# EFR32MG24A020F1536IM40 register map
Vendor: Silicon Labs; Series: EFR32; File version: B
Registers are 32-bit, read-write, reset 0x0 unless marked. A register's access mark holds for its fields unless they carry their own. Offsets are from the block's base; [hi:lo] are bit positions; {n}, {i} and the like mark numbered series; 'fields as' and 'values as' point back to an identical list.

## MSC_NS — MSC_NS Registers
Base 0x50030000
Same registers: MSC_S 0x40030000
0x00 IPVERSION ro reset 0x3
  [31:0] IPVERSION — IP Version ID
0x04 READCTRL reset 0x200000
  [21:20] MODE — Read Mode
    0=WS0 (Zero wait-states inserted in fetch or read transfers); 1=WS1 (One wait-state inserted for each fetch or read transfer. See Flash Wait-States table for details); 2=WS2 (Two wait-states inserted for eatch fetch or read transfer. See Flash Wait-States table for details); 3=WS3 (Three wait-states inserted for eatch fetch or read transfer. See Flash Wait-States table for details)
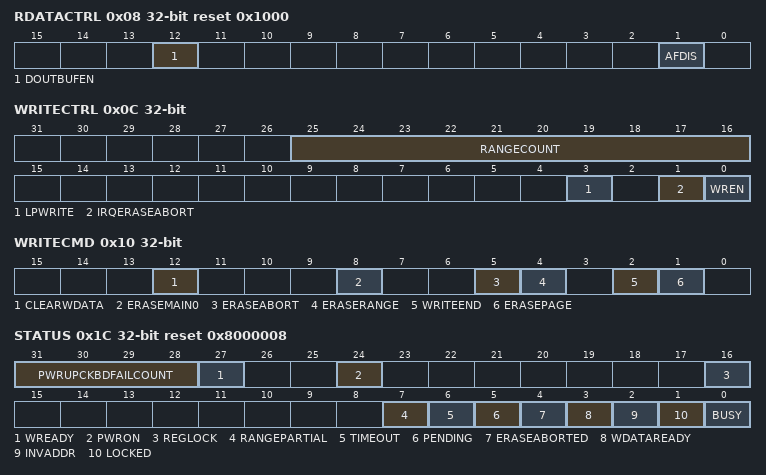
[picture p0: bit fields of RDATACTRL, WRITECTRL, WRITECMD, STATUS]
0x08 RDATACTRL reset 0x1000
  [12] DOUTBUFEN — Flash dout pipeline buffer enable
  [1] AFDIS — Automatic Invalidate Disable
0x0C WRITECTRL
  [25:16] RANGECOUNT — EraseRange Count
  [3] LPWRITE — Low-Power Write
  [1] IRQERASEABORT — Abort Page Erase on Interrupt
  [0] WREN — Enable Write/Erase Controller
0x10 WRITECMD wo
  [12] CLEARWDATA — Clear WDATA state
  [8] ERASEMAIN0 — Mass erase region 0
  [5] ERASEABORT — Abort erase sequence
  [4] ERASERANGE — Erase range of pages
  [2] WRITEEND — End Write Mode
  [1] ERASEPAGE
0x14 ADDRB
  [31:0] ADDRB — Page Erase or Write Address Buffer
0x18 WDATA
  [31:0] DATAW — Write Data
0x1C STATUS ro reset 0x8000008
  [31:28] PWRUPCKBDFAILCOUNT — Flash power up checkerboard pattern chec
  [27] WREADY — Flash Write Ready
  [24] PWRON — Flash power on status
  [16] REGLOCK — Register Lock Status
    0=UNLOCKED; 1=LOCKED
  [7] RANGEPARTIAL — EraseRange with skipped locked pages
  [6] TIMEOUT — Write Command Timeout
  [5] PENDING — Write Command In Queue
  [4] ERASEABORTED — Erase Operation Aborted
  [3] WDATAREADY — WDATA Write Ready
  [2] INVADDR — Invalid Write Address or Erase Page
  [1] LOCKED — Access Locked
  [0] BUSY — Erase/Write Busy
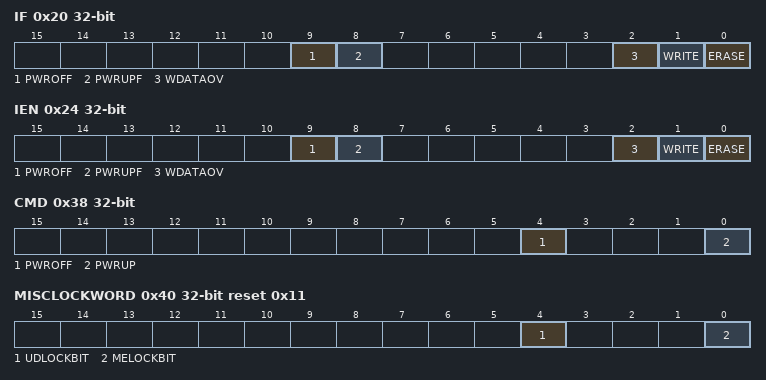
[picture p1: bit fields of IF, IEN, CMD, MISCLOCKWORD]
0x20 IF
  [9] PWROFF — Flash Power Off Sequence Complete Flag
  [8] PWRUPF — Flash Power Up Sequence Complete Flag
  [2] WDATAOV — Host write buffer overflow
  [1] WRITE — Host Write Done Interrupt Read Flag
  [0] ERASE — Host Erase Done Interrupt Read Flag
0x24 IEN
  [9] PWROFF — Flash Power Off Seq done irq enable
  [8] PWRUPF — Flash Power Up Seq done irq enable
  [2] WDATAOV — write data buffer overflow irq enable
  [1] WRITE — Write Done Interrupt enable
  [0] ERASE — Erase Done Interrupt enable
0x34 USERDATASIZE ro reset 0x4
  [5:0] USERDATASIZE
0x38 CMD wo
  [4] PWROFF — Flash power off/sleep command
  [0] PWRUP — Flash Power Up Command
0x3C LOCK wo
  [15:0] LOCKKEY — Configuration Lock
    0=LOCK; 0x1B71=UNLOCK
0x40 MISCLOCKWORD reset 0x11
  [4] UDLOCKBIT — User Data Lock
  [0] MELOCKBIT — Mass Erase Lock
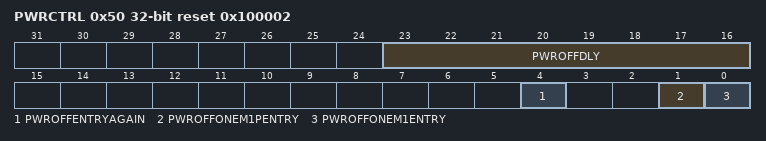
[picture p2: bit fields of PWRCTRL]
0x50 PWRCTRL reset 0x100002
  [23:16] PWROFFDLY — Power down delay
  [4] PWROFFENTRYAGAIN — POWER down flash again in EM1/EM1p
  [1] PWROFFONEM1PENTRY — Power down Flash macro when enter EM1P
  [0] PWROFFONEM1ENTRY — Power down Flash macro when enter EM1
{0x120+4i} PAGELOCK{i} (i=0..5)
  [31:0] LOCKBIT — page lock bit

## PCNT0_NS — PCNT0_NS Registers
Base 0x59030000
Same registers: PCNT0_S 0x49030000
0x00 IPVERSION ro reset 0x1
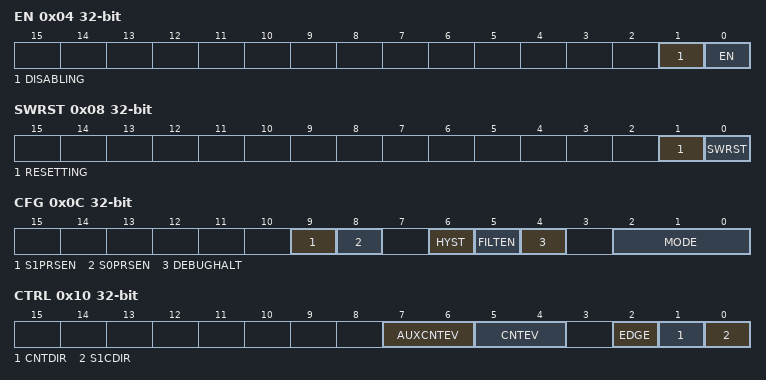
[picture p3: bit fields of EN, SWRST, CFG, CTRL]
0x04 EN
  [1] DISABLING ro — Disablement busy status
  [0] EN — PCNT Module Enable
0x08 SWRST
  [1] RESETTING ro — Software reset busy status
  [0] SWRST wo — Software reset command
0x0C CFG
  [9] S1PRSEN — S1IN PRS Enable
  [8] S0PRSEN — S0IN PRS Enable
  [6] HYST — Enable Hysteresis
  [5] FILTEN — Enable Digital Pulse Width Filter
  [4] DEBUGHALT — Debug Mode Halt Enable
    0=DISABLE (PCNT is running in debug mode.); 1=ENABLE (PCNT is frozen in debug mode.)
  [2:0] MODE — Mode Select
    0=OVSSINGLE (Single input EM23GRPACLK oversampling mode (available in EM0-EM3).); 1=EXTCLKSINGLE (Externally clocked single input counter mode (available in EM0-EM3).); 2=EXTCLKQUAD (Externally clocked quadrature decoder mode (available in EM0-EM3).); 3=OVSQUAD1X (EM23GRPACLK oversampling quadrature decoder 1X mode (available in EM0-EM3).); 4=OVSQUAD2X (EM23GRPACLK oversampling quadrature decoder 2X mode (available in EM0-EM3).); 5=OVSQUAD4X (EM23GRPACLK oversampling quadrature decoder 4X mode (available in EM0-EM3).)
0x10 CTRL
  [7:6] AUXCNTEV — Controls When the Aux Counter Counts
    0=BOTH (Counts up on both up-count and down-count events.); 1=UP (Counts up on up-count events.); 2=DOWN (Counts up on down-count events.)
  [5:4] CNTEV — Controls When the Counter Counts
    0=BOTH (Counts up on up-count and down on down-count events.); 1=UP (Only counts up on up-count events.); 2=DOWN (Only counts down on down-count events.)
  [2] EDGE — Edge Select
    0=POS (Positive edges on the PCNTn_S0IN inputs are counted in OVSSINGLE mode. Does not invert PCNTn_S1IN input in OVSSINGLE and EXTCLKSINGLE modes); 1=NEG (Negative edges on the PCNTn_S0IN inputs are counted in OVSSINGLE mode. Inverts the PCNTn_S1IN input in OVSSINGLE and EXTCLKSINGLE modes)
  [1] CNTDIR — Non-Quadrature Mode Counter Direction Co
    0=UP (Up counter mode.); 1=DOWN (Down counter mode.)
  [0] S1CDIR — Count Direction Determined By S1
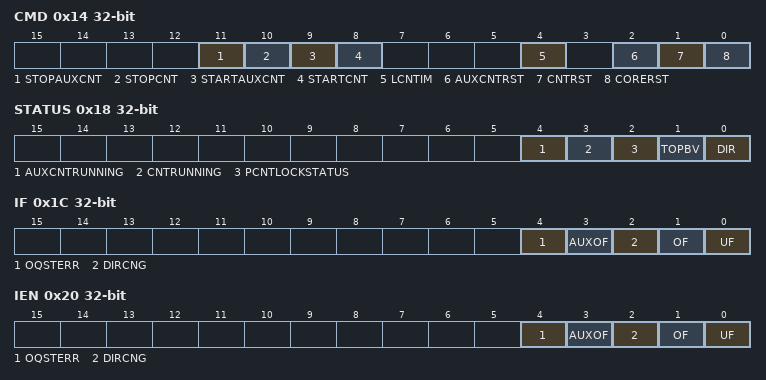
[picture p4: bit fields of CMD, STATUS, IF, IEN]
0x14 CMD wo
  [11] STOPAUXCNT — Stop Aux Counter
  [10] STOPCNT — Stop Main Counter
  [9] STARTAUXCNT — Start Aux Counter
  [8] STARTCNT — Start Main Counter
  [4] LCNTIM — Load CNT Immediately
  [2] AUXCNTRST — AUXCNT Reset
  [1] CNTRST — CNT Reset
  [0] CORERST — PCNT Clock Domain Reset
0x18 STATUS ro
  [4] AUXCNTRUNNING — Aux Counter running status
  [3] CNTRUNNING — Main Counter running status
  [2] PCNTLOCKSTATUS — Lock Status
    0=UNLOCKED (PCNT registers are unlocked); 1=LOCKED (PCNT registers are locked)
  [1] TOPBV — TOP Buffer Valid
  [0] DIR — Current Counter Direction
    0=UP (Up counter mode (clockwise in EXTCLKQUAD mode with the EDGE bit in PCNTn_CTRL set to 0).); 1=DOWN (Down counter mode.)
0x1C IF
  [4] OQSTERR — Oversampling Quad State Err Int Flag
  [3] AUXOF — Auxiliary Overflow Interrupt Read Flag
  [2] DIRCNG — Direction Change Detect Interrupt Flag
  [1] OF — Overflow Interrupt Read Flag
  [0] UF — Underflow Interrupt Read Flag
0x20 IEN
  fields as IF
0x24 CNT ro
  [15:0] CNT — Counter Value
0x28 AUXCNT ro
  [15:0] AUXCNT — Auxiliary Counter Value
0x2C TOP reset 0xFF
  [15:0] TOP — Counter Top Value
0x30 TOPB reset 0xFF
  [15:0] TOPB — Counter Top Buffer Register
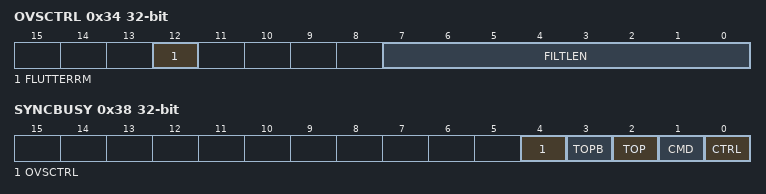
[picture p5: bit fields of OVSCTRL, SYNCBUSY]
0x34 OVSCTRL
  [12] FLUTTERRM — Flutter Remove
  [7:0] FILTLEN — Configure Filter Length for Inputs S0IN
0x38 SYNCBUSY ro
  [4] OVSCTRL — OVSCTRL Register Busy
  [3] TOPB — TOPB Register Busy
  [2] TOP — TOP Register Busy
  [1] CMD — CMD Register Busy
  [0] CTRL — CTRL Register Busy
0x3C LOCK wo
  [15:0] PCNTLOCKKEY — Configuration Lock Key
    0xA7E0=UNLOCK (Write to unock PCNT lockable registers)
